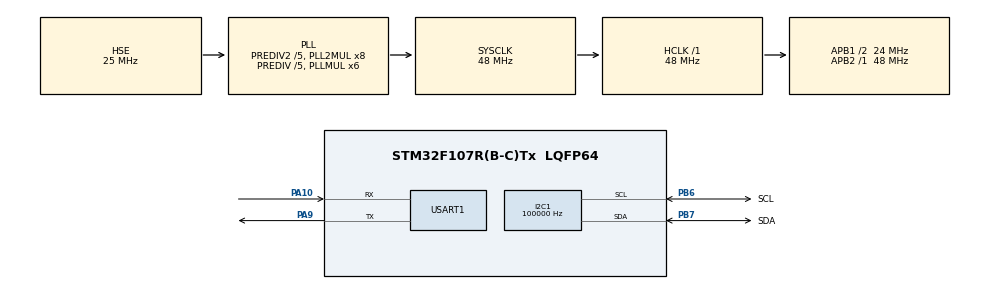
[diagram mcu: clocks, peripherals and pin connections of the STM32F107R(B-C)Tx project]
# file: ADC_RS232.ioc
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I2C1.ClockSpeed=100000
I2C1.I2C_Mode=I2C_Standard
Mcu.Family=STM32F1
Mcu.Name=STM32F107R(B-C)Tx
Mcu.Package=LQFP64
NVIC.PriorityGroup=NVIC_PRIORITYGROUP_4
NVIC.USART1_IRQn=true\:0\:0\:false\:false\:true\:true\:true
PA10.Mode=Asynchronous
PA10.Signal=USART1_RX
PA13.Mode=Serial_Wire
PA13.Signal=SYS_JTMS-SWDIO
PA14.Mode=Serial_Wire
PA14.Signal=SYS_JTCK-SWCLK
PA9.Mode=Asynchronous
PA9.Signal=USART1_TX
PB6.GPIO_Label=SCL
PB6.Mode=I2C
PB6.Signal=I2C1_SCL
PB7.GPIO_Label=SDA
PB7.Mode=I2C
PB7.Signal=I2C1_SDA
PD0-OSC_IN.Mode=HSE-External-Oscillator
PD0-OSC_IN.Signal=RCC_OSC_IN
PD1-OSC_OUT.Mode=HSE-External-Oscillator
PD1-OSC_OUT.Signal=RCC_OSC_OUT
ProjectManager.HeapSize=0x200
ProjectManager.StackSize=0x400
ProjectManager.TargetToolchain=MDK-ARM V5.27
RCC.AHBFreq_Value=48000000
RCC.APB1CLKDivider=RCC_HCLK_DIV2
RCC.APB1Freq_Value=24000000
RCC.APB1TimFreq_Value=48000000
RCC.APB2Freq_Value=48000000
RCC.APB2TimFreq_Value=48000000
RCC.HCLKFreq_Value=48000000
RCC.HSEDivPLL=RCC_HSE_PREDIV_DIV5
RCC.HSE_VALUE=25000000
RCC.PLLMUL=RCC_PLL_MUL6
RCC.PLLSourceVirtual=RCC_PLLSOURCE_HSE
RCC.Prediv1Source=RCC_PREDIV1_SOURCE_PLL2
RCC.Prediv2=RCC_HSE_PREDIV2_DIV5
RCC.SYSCLKFreq_VALUE=48000000
RCC.SYSCLKSource=RCC_SYSCLKSOURCE_PLLCLK
RCC.USBFreq_Value=32000000
USART1.VirtualMode=VM_ASYNC
board=custom

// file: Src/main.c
/* USER CODE BEGIN Header */
/**
  ******************************************************************************
  * @file           : main.c
  * @brief          : Main program body
  ******************************************************************************
  * @attention
  *
  * <h2><center>&copy; Copyright (c) 2020 STMicroelectronics.
  * All rights reserved.</center></h2>
  *
  * This software component is licensed by ST under BSD 3-Clause license,
  * the "License"; You may not use this file except in compliance with the
  * License. You may obtain a copy of the License at:
  *                        opensource.org/licenses/BSD-3-Clause
  *
  ******************************************************************************
  */
/* USER CODE END Header */

#include "main.h"

/* USER CODE BEGIN Includes */
#include "string.h"
#include "stdio.h"
/* USER CODE END Includes */

I2C_HandleTypeDef hi2c1;

UART_HandleTypeDef huart1;

void SystemClock_Config(void);
static void MX_GPIO_Init(void);
static void MX_I2C1_Init(void);
static void MX_USART1_UART_Init(void);

int main(void)
{

  /* MCU Configuration--------------------------------------------------------*/

  /* Reset of all peripherals, Initializes the Flash interface and the Systick. */
  HAL_Init();

  /* Configure the system clock */
  SystemClock_Config();

  /* Initialize all configured peripherals */
  MX_GPIO_Init();
  MX_I2C1_Init();
  MX_USART1_UART_Init();
  /* USER CODE BEGIN 2 */
	uint16_t ADC_addr=0x69;
	//ADC_addr=(ADC_addr<<1)||0x0001;

  uint16_t data;
	uint8_t uart_buf[20]={0};
	HAL_Delay(2000);

  /* USER CODE END 2 */

  /* Infinite loop */
  /* USER CODE BEGIN WHILE */
  while (1)
  {

	  //HAL_UART_Transmit(&huart1,"uart1\r\n",7,100);

		HAL_I2C_Master_Receive(&hi2c1,ADC_addr,(uint8_t*)&data,2,1000);
	  sprintf(uart_buf,"adc:%d\r\n",data);
		HAL_UART_Transmit(&huart1,uart_buf,strlen(uart_buf),100);

		/*
		if(HAL_I2C_IsDeviceReady(&hi2c1,ADC_addr,1,100)==HAL_OK)
		{
		  sprintf(uart_buf,"ADC:%d\r\n",ADC_addr);
		  HAL_UART_Transmit(&huart1,uart_buf,strlen(uart_buf),100);
		}

		ADC_addr++;
		ADC_addr=ADC_addr%0x80;
		*/
		HAL_Delay(1000);
    /* USER CODE END WHILE */

  }
}

void SystemClock_Config(void)
{
  RCC_OscInitTypeDef RCC_OscInitStruct = {0};
  RCC_ClkInitTypeDef RCC_ClkInitStruct = {0};

  /** Initializes the CPU, AHB and APB busses clocks
  */
  RCC_OscInitStruct.OscillatorType = RCC_OSCILLATORTYPE_HSE;
  RCC_OscInitStruct.HSEState = RCC_HSE_ON;
  RCC_OscInitStruct.HSEPredivValue = RCC_HSE_PREDIV_DIV5;
  RCC_OscInitStruct.HSIState = RCC_HSI_ON;
  RCC_OscInitStruct.Prediv1Source = RCC_PREDIV1_SOURCE_PLL2;
  RCC_OscInitStruct.PLL.PLLState = RCC_PLL_ON;
  RCC_OscInitStruct.PLL.PLLSource = RCC_PLLSOURCE_HSE;
  RCC_OscInitStruct.PLL.PLLMUL = RCC_PLL_MUL6;
  RCC_OscInitStruct.PLL2.PLL2State = RCC_PLL2_ON;
  RCC_OscInitStruct.PLL2.PLL2MUL = RCC_PLL2_MUL8;
  RCC_OscInitStruct.PLL2.HSEPrediv2Value = RCC_HSE_PREDIV2_DIV5;
  if (HAL_RCC_OscConfig(&RCC_OscInitStruct) != HAL_OK)
  {
    Error_Handler();
  }
  /** Initializes the CPU, AHB and APB busses clocks
  */
  RCC_ClkInitStruct.ClockType = RCC_CLOCKTYPE_HCLK|RCC_CLOCKTYPE_SYSCLK
                              |RCC_CLOCKTYPE_PCLK1|RCC_CLOCKTYPE_PCLK2;
  RCC_ClkInitStruct.SYSCLKSource = RCC_SYSCLKSOURCE_PLLCLK;
  RCC_ClkInitStruct.AHBCLKDivider = RCC_SYSCLK_DIV1;
  RCC_ClkInitStruct.APB1CLKDivider = RCC_HCLK_DIV2;
  RCC_ClkInitStruct.APB2CLKDivider = RCC_HCLK_DIV1;

  if (HAL_RCC_ClockConfig(&RCC_ClkInitStruct, FLASH_LATENCY_1) != HAL_OK)
  {
    Error_Handler();
  }
  /** Configure the Systick interrupt time
  */
  __HAL_RCC_PLLI2S_ENABLE();
}

static void MX_I2C1_Init(void)
{

  hi2c1.Instance = I2C1;
  hi2c1.Init.ClockSpeed = 100000;
  hi2c1.Init.DutyCycle = I2C_DUTYCYCLE_2;
  hi2c1.Init.OwnAddress1 = 0;
  hi2c1.Init.AddressingMode = I2C_ADDRESSINGMODE_7BIT;
  hi2c1.Init.DualAddressMode = I2C_DUALADDRESS_DISABLE;
  hi2c1.Init.OwnAddress2 = 0;
  hi2c1.Init.GeneralCallMode = I2C_GENERALCALL_DISABLE;
  hi2c1.Init.NoStretchMode = I2C_NOSTRETCH_DISABLE;
  if (HAL_I2C_Init(&hi2c1) != HAL_OK)
  {
    Error_Handler();
  }

}

static void MX_USART1_UART_Init(void)
{

  huart1.Instance = USART1;
  huart1.Init.BaudRate = 115200;
  huart1.Init.WordLength = UART_WORDLENGTH_8B;
  huart1.Init.StopBits = UART_STOPBITS_1;
  huart1.Init.Parity = UART_PARITY_NONE;
  huart1.Init.Mode = UART_MODE_TX_RX;
  huart1.Init.HwFlowCtl = UART_HWCONTROL_NONE;
  huart1.Init.OverSampling = UART_OVERSAMPLING_16;
  if (HAL_UART_Init(&huart1) != HAL_OK)
  {
    Error_Handler();
  }

}

static void MX_GPIO_Init(void)
{

  /* GPIO Ports Clock Enable */
  __HAL_RCC_GPIOD_CLK_ENABLE();
  __HAL_RCC_GPIOA_CLK_ENABLE();
  __HAL_RCC_GPIOB_CLK_ENABLE();

}

void Error_Handler(void)
{
}

/************************ (C) COPYRIGHT STMicroelectronics *****END OF FILE****/
